# PT32x063xx register map
File version: 0.1
Registers are 32-bit, read-write, reset 0x0 unless marked. A register's access mark holds for its fields unless they carry their own. Offsets are from the block's base; [hi:lo] are bit positions; {n}, {i} and the like mark numbered series.

## ES — Device Electronic Signature
Base 0x40020800
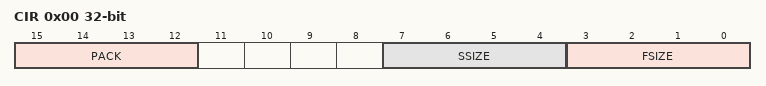
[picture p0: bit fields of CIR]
0x00 CIR ro — Chip Information Register
  [15:12] PACK — Package
  [7:4] SSIZE — Size of sram memory
  [3:0] FSIZE — Size of flash memory
0x0C CIDR1 ro reset 0xFFFFFFFF — Chip ID Register 1
  [31:0] CID — Chip ID
0x10 CIDR2 ro — Chip ID Register 2
  [31:0] CID — Chip ID
0x14 CIDR3 ro — Chip ID Register 3
  [31:0] CID — Chip ID
{0x14+4i} UDIR{i} reset 0xFFFFFFFF (i=1..3) — User-Defined Information Register {i}
  [31:0] INFO — User-defined information

## BEEP
Base 0x40002800
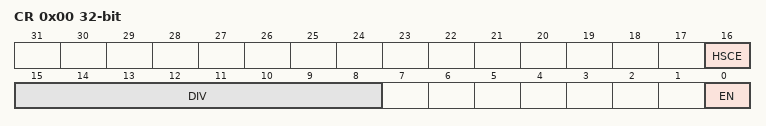
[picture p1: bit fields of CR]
0x00 CR — Control Register
  [16] HSCE — BEEP high sink current enable
  [15:8] DIV — BEEP Clock divider
  [0] EN — BEEP enable

## IRTIM — Infrared Timer
Base 0x40008400
0x00 CR — Control Register
  [0] EN — IRTIM enable
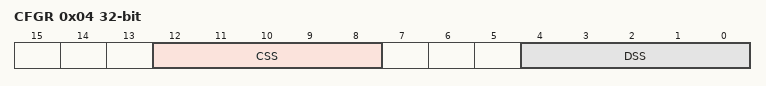
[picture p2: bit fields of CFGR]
0x04 CFGR — Configuration Register
  [12:8] CSS — Carrier source selection
  [4:0] DSS — Data source selection

## LCD — Liquid Crystal Display
Base 0x40015000
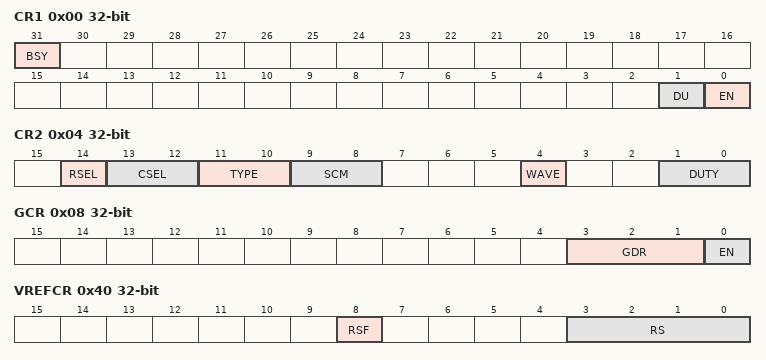
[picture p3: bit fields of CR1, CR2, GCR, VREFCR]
0x00 CR1 — Control Register 1
  [31] BSY — Register busy
  [1] DU — Display data update
  [0] EN — LCD enable
0x04 CR2 — Control Register 2
  [14] RSEL — R-drive total resistance selection
  [13:12] CSEL — C-drive mode selection
  [11:10] TYPE — LCD drive voltage type
  [9:8] SCM — Screen Control mode
  [4] WAVE — waveform control
  [1:0] DUTY — LCD duty cycle
0x08 GCR — Grayscale Control Register
  [3:1] GDR — Grayscale adjustment control
  [0] EN — Grayscale Control Enable
0x0C PSCR — Prescaler Register
  [4:0] PSC — Prescaler
0x10 BTCR — Blink Time Control Register
  [7:0] BT — Blink Time
0x14 BONCR — Blink On Control Register
  [7:0] ON — Blinking Lighting Time
0x18 PCR1 — Port Control Register 1
  [31:0] PE — LCDx pin enable
0x1C PCR2 — Port Control Register 2
  [31:0] PE — LCDx pin enable
0x20 PDCR1 — Port Driver Control Register 1
  [31:0] PDC — LCDx pin driver control
0x24 PDCR2 — Port Driver Control Register 2
  [15:0] PDC — LCDx pin pin driver control
0x40 VREFCR access per field — Reference Voltage Control Register
  [8] RSF ro — LCD VREF status flag
  [3:0] RS rw — Reference voltage selection

## RTC — Real Time Clock
Base 0x40013C00
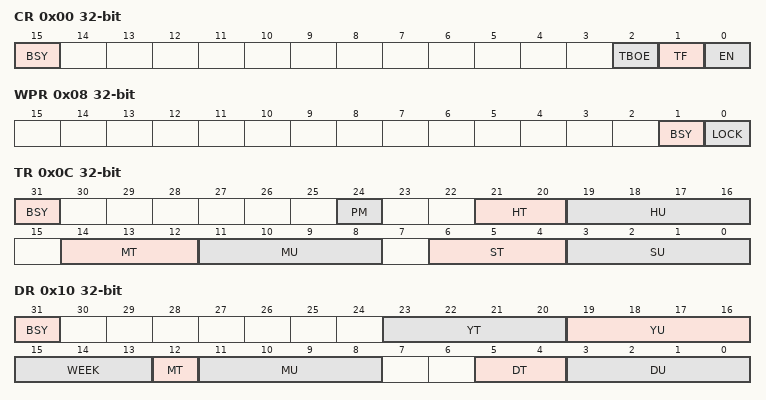
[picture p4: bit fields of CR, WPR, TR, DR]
0x00 CR — Control Register
  [15] BSY — Register busy
  [2] TBOE — Time beacon output enable
  [1] TF — Time format
  [0] EN — RTC enable
0x04 CFGR — Configuration Register
  [15:0] PINT — Periodic Interrupt Interval
0x08 WPR ro — Write Protection Register
  [1] BSY — Register busy
  [0] LOCK — Lock status
0x0C TR — Time Register
  [31] BSY — Register busy
  [24] PM — AM/PM notation
  [21:20] HT — Hour tens in BCD format
  [19:16] HU — Hour units in BCD format
  [14:12] MT — Minute tens in BCD format
  [11:8] MU — Minute units in BCD format
  [6:4] ST — Second tens in BCD format
  [3:0] SU — Second units in BCD format
0x10 DR — Date Register
  [31] BSY — Register busy
  [23:20] YT — Year tens in BCD format
  [19:16] YU — Year units in BCD format
  [15:13] WEEK — Week day
  [12] MT — Month tens in BCD format
  [11:8] MU — Month units in BCD format
  [5:4] DT — Day tens in BCD format
  [3:0] DU — Day units in BCD format
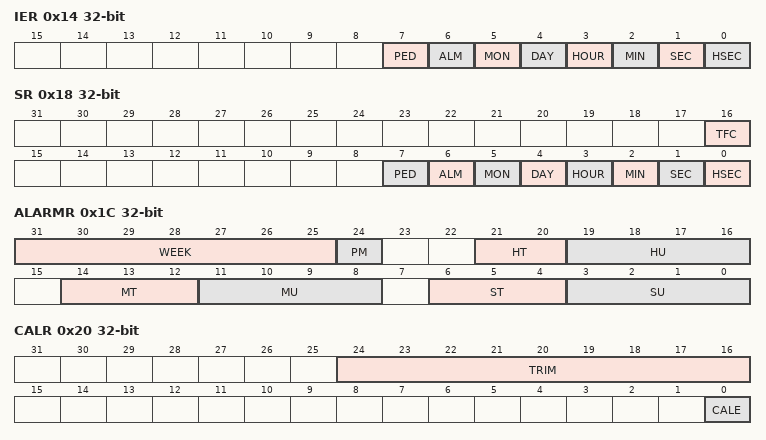
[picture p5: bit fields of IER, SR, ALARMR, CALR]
0x14 IER — Interrupt Enable Register
  [7] PED — Periodic interrupt enable
  [6] ALM — Alarm interrupt enable
  [5] MON — Month update interrupt enable
  [4] DAY — Day update interrupt enable
  [3] HOUR — Hour update interrupt enable
  [2] MIN — Minute update interrupt enable
  [1] SEC — Second update interrupt enable
  [0] HSEC — Half-second update interrupt enable
0x18 SR access per field — Status Register
  [16] TFC ro — Time format changed Flag
  [7] PED rw — Periodic update flag
  [6] ALM rw — Alarm flag
  [5] MON rw — Month update flag
  [4] DAY rw — Day update flag
  [3] HOUR rw — Hour update flag
  [2] MIN rw — Minute update flag
  [1] SEC rw — Second update flag
  [0] HSEC rw — Half-second update flag
0x1C ALARMR — Alarm Register
  [31:25] WEEK
  [24] PM — P.M flag
  [21:20] HT — Hour tens in BCD format
  [19:16] HU — Hour units in BCD format
  [14:12] MT — Minute tens in BCD format
  [11:8] MU — Minute units in BCD format
  [6:4] ST — Second tens in BCD format
  [3:0] SU — Second units in BCD format
0x20 CALR — Calibration Register
  [24:16] TRIM — Trim Value
  [0] CALE — Calibration mode enable

## AES — Advanced Encryption Standard
Base 0x40013400
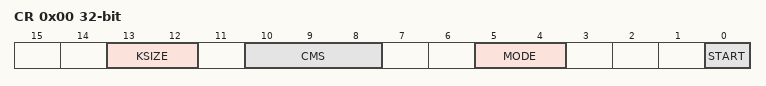
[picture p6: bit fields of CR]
0x00 CR access per field — Control Register
  [13:12] KSIZE rw — Key size selection
  [10:8] CMS rw — Chaining mode selection
  [5:4] MODE rw — AES operating mode
  [0] START wo — Start computation
0x04 IER — Interrupt Enable Register
  [0] CC — Computation completed interrupt enable
0x08 SR ro — Status Register
  [0] CC — Computation completed flag
{0x10+4i} KR{i} (i=0..7) — Key Register {i}
  [31:0] KEY
{0x30+4i} IVR{i} (i=0..3) — Initialization Vector Register {i}
  [31:0] IVI — Initialization vector input
{0x40+4i} DINR{i} (i=0..3) — Data Input Register {i}
  [31:0] DIN — Data input
{0x60+4i} DOUT{i} ro (i=0..3) — Data Output Register {i}
  [31:0] DOUT — Data output
